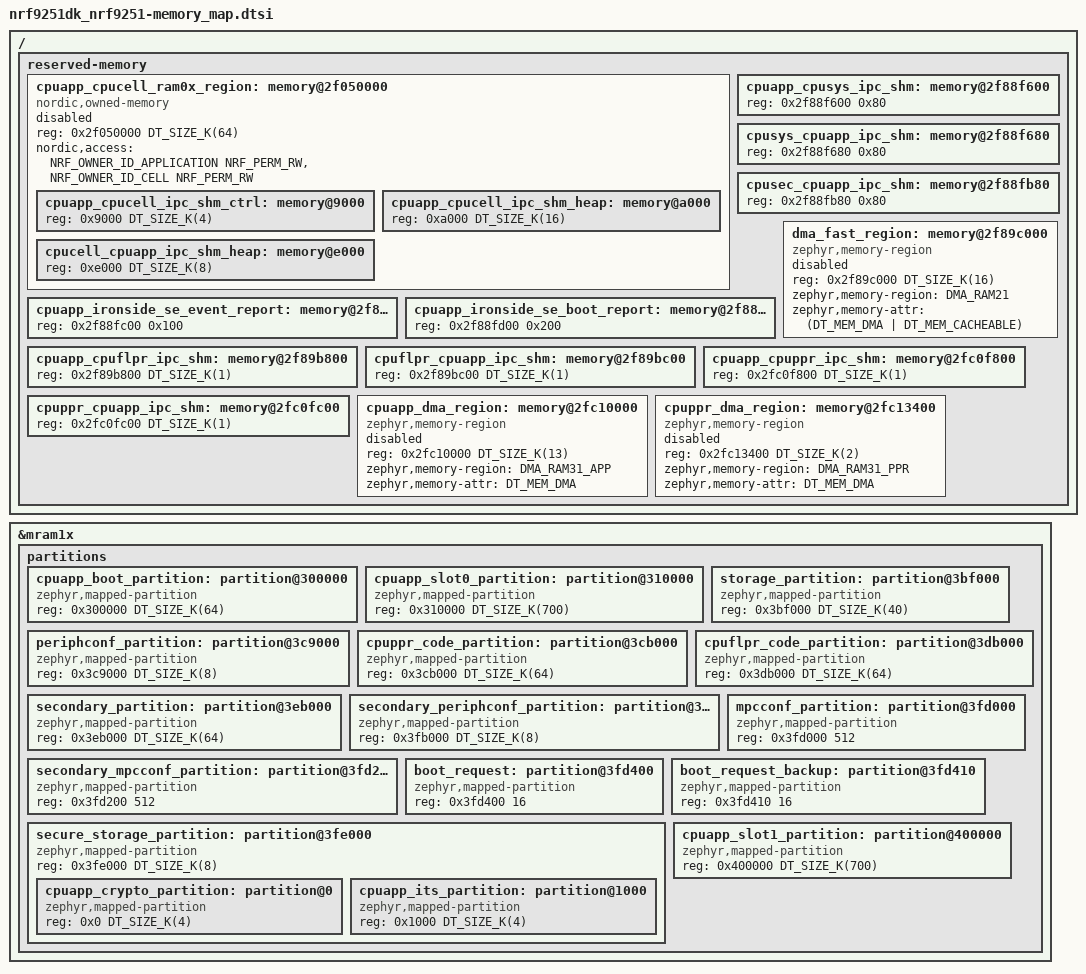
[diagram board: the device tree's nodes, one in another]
/*
 * Copyright (c) 2026 Nordic Semiconductor ASA
 *
 * SPDX-License-Identifier: LicenseRef-Nordic-5-Clause
 */

#include <zephyr/dt-bindings/memory-attr/memory-attr.h>
#include <zephyr/dt-bindings/reserved-memory/nordic-owned-memory.h>

/ {
	reserved-memory {
		#address-cells = <1>;
		#size-cells = <1>;
		ranges;

		cpuapp_cpucell_ram0x_region: memory@2f050000 {
			compatible = "nordic,owned-memory";
			reg = <0x2f050000 DT_SIZE_K(64)>;
			status = "disabled";
			nordic,access = <NRF_OWNER_ID_APPLICATION NRF_PERM_RW>,
					<NRF_OWNER_ID_CELL NRF_PERM_RW>;
			#address-cells = <1>;
			#size-cells = <1>;
			ranges = <0x0 0x2f050000 0x10000>;

			/* IPC Ctrl */
			cpuapp_cpucell_ipc_shm_ctrl: memory@9000 {
				reg = <0x9000 DT_SIZE_K(4)>;
			};

			/* IPC TX heap, user defined */
			cpuapp_cpucell_ipc_shm_heap: memory@a000 {
				reg = <0xa000 DT_SIZE_K(16)>;
			};

			/* IPC RX heap, user defined */
			cpucell_cpuapp_ipc_shm_heap: memory@e000 {
				reg = <0xe000 DT_SIZE_K(8)>;
			};
		};

		cpuapp_cpusys_ipc_shm: memory@2f88f600 {
			reg = <0x2f88f600 0x80>;
		};

		cpusys_cpuapp_ipc_shm: memory@2f88f680 {
			reg = <0x2f88f680 0x80>;
		};

		cpusec_cpuapp_ipc_shm: memory@2f88fb80 {
			reg = <0x2f88fb80 0x80>;
		};

		cpuapp_ironside_se_event_report: memory@2f88fc00 {
			reg = <0x2f88fc00 0x100>;
		};

		cpuapp_ironside_se_boot_report: memory@2f88fd00 {
			reg = <0x2f88fd00 0x200>;
		};

		cpuapp_cpuflpr_ipc_shm: memory@2f89b800 {
			reg = <0x2f89b800 DT_SIZE_K(1)>;
		};

		cpuflpr_cpuapp_ipc_shm: memory@2f89bc00 {
			reg = <0x2f89bc00 DT_SIZE_K(1)>;
		};

		dma_fast_region: memory@2f89c000 {
			compatible = "zephyr,memory-region";
			reg = <0x2f89c000 DT_SIZE_K(16)>;
			status = "disabled";
			#memory-region-cells = <0>;
			zephyr,memory-region = "DMA_RAM21";
			zephyr,memory-attr = <(DT_MEM_DMA | DT_MEM_CACHEABLE)>;
		};

		cpuapp_cpuppr_ipc_shm: memory@2fc0f800 {
			reg = <0x2fc0f800 DT_SIZE_K(1)>;
		};

		cpuppr_cpuapp_ipc_shm: memory@2fc0fc00 {
			reg = <0x2fc0fc00 DT_SIZE_K(1)>;
		};

		cpuapp_dma_region: memory@2fc10000 {
			compatible = "zephyr,memory-region";
			reg = <0x2fc10000 DT_SIZE_K(13)>;
			status = "disabled";
			#memory-region-cells = <0>;
			zephyr,memory-region = "DMA_RAM31_APP";
			zephyr,memory-attr = <DT_MEM_DMA>;
		};

		cpuppr_dma_region: memory@2fc13400 {
			compatible = "zephyr,memory-region";
			reg = <0x2fc13400 DT_SIZE_K(2)>;
			status = "disabled";
			#memory-region-cells = <0>;
			zephyr,memory-region = "DMA_RAM31_PPR";
			zephyr,memory-attr = <DT_MEM_DMA>;
		};

		/* 0x2fc13c00 - 0x2fc14000 reserved for Cellular core. */
	};
};

&mram1x {
	partitions {
		#address-cells = <1>;
		#size-cells = <1>;
		ranges;

		cpuapp_boot_partition: partition@300000 {
			compatible = "zephyr,mapped-partition";
			reg = <0x300000 DT_SIZE_K(64)>;
		};

		cpuapp_slot0_partition: partition@310000 {
			compatible = "zephyr,mapped-partition";
			reg = <0x310000 DT_SIZE_K(700)>;
		};

		storage_partition: partition@3bf000 {
			compatible = "zephyr,mapped-partition";
			reg = <0x3bf000 DT_SIZE_K(40)>;
		};

		periphconf_partition: partition@3c9000 {
			compatible = "zephyr,mapped-partition";
			reg = <0x3c9000 DT_SIZE_K(8)>;
		};

		cpuppr_code_partition: partition@3cb000 {
			compatible = "zephyr,mapped-partition";
			reg = <0x3cb000 DT_SIZE_K(64)>;
		};

		cpuflpr_code_partition: partition@3db000 {
			compatible = "zephyr,mapped-partition";
			reg = <0x3db000 DT_SIZE_K(64)>;
		};

		secondary_partition: partition@3eb000 {
			compatible = "zephyr,mapped-partition";
			reg = <0x3eb000 DT_SIZE_K(64)>;
		};

		secondary_periphconf_partition: partition@3fb000 {
			compatible = "zephyr,mapped-partition";
			reg = <0x3fb000 DT_SIZE_K(8)>;
		};

		mpcconf_partition: partition@3fd000 {
			compatible = "zephyr,mapped-partition";
			reg = <0x3fd000 512>;
		};

		secondary_mpcconf_partition: partition@3fd200 {
			compatible = "zephyr,mapped-partition";
			reg = <0x3fd200 512>;
		};

		boot_request: partition@3fd400 {
			compatible = "zephyr,mapped-partition";
			reg = <0x3fd400 16>;
		};

		boot_request_backup: partition@3fd410 {
			compatible = "zephyr,mapped-partition";
			reg = <0x3fd410 16>;
		};

		secure_storage_partition: partition@3fe000 {
			compatible = "zephyr,mapped-partition";
			reg = <0x3fe000 DT_SIZE_K(8)>;
			ranges = <0x0 0x3fe000 0x2000>;
			#address-cells = <1>;
			#size-cells = <1>;

			cpuapp_crypto_partition: partition@0 {
				compatible = "zephyr,mapped-partition";
				reg = <0x0 DT_SIZE_K(4)>;
			};

			cpuapp_its_partition: partition@1000 {
				compatible = "zephyr,mapped-partition";
				reg = <0x1000 DT_SIZE_K(4)>;
			};
		};

		cpuapp_slot1_partition: partition@400000 {
			compatible = "zephyr,mapped-partition";
			reg = <0x400000 DT_SIZE_K(700)>;
		};
	};
};
